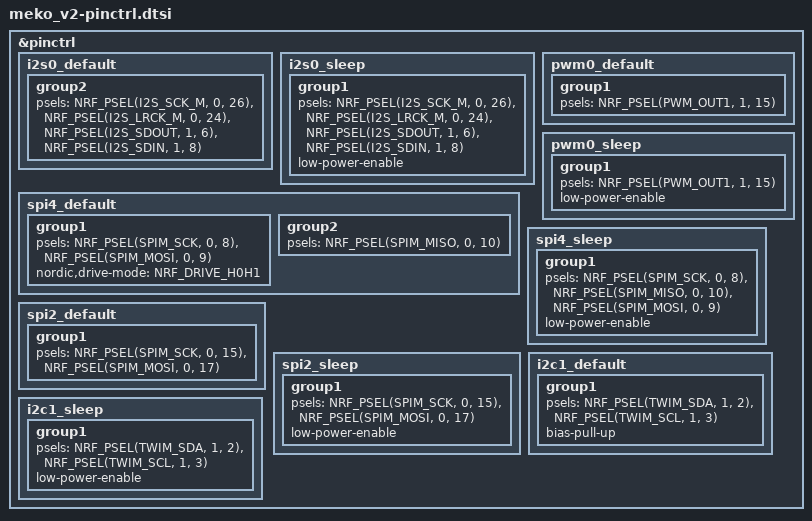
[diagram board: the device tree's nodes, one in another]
&pinctrl {
    i2s0_default: i2s0_default {
        group2 {
            psels = <NRF_PSEL(I2S_SCK_M, 0, 26)>,
                    <NRF_PSEL(I2S_LRCK_M, 0, 24)>,
                    <NRF_PSEL(I2S_SDOUT, 1, 6)>,
                    <NRF_PSEL(I2S_SDIN, 1, 8)>;
        };
    };

    i2s0_sleep: i2s0_sleep {
        group1 {
            psels = <NRF_PSEL(I2S_SCK_M, 0, 26)>,
                    <NRF_PSEL(I2S_LRCK_M, 0, 24)>,
                    <NRF_PSEL(I2S_SDOUT, 1, 6)>,
                    <NRF_PSEL(I2S_SDIN, 1, 8)>;
            low-power-enable;
        };
    };

    pwm0_default: pwm0_default {
        group1 {
            psels = <NRF_PSEL(PWM_OUT1, 1, 15)>;
        };
    };

    pwm0_sleep: pwm0_sleep {
        group1 {
            psels = <NRF_PSEL(PWM_OUT1, 1, 15)>;
            low-power-enable;
        };
    };

    spi4_default: spi4_default {
        group1 {
            psels = <NRF_PSEL(SPIM_SCK, 0, 8)>,
                    <NRF_PSEL(SPIM_MOSI, 0, 9)>;
            /* Workaround for issue with PCA10121 v0.7.0
             * related to SD-card
             */
            nordic,drive-mode = <NRF_DRIVE_H0H1>;
        };

        group2 {
            psels = <NRF_PSEL(SPIM_MISO, 0, 10)>;
        };
    };

    spi4_sleep: spi4_sleep {
        group1 {
            psels = <NRF_PSEL(SPIM_SCK, 0, 8)>,
                    <NRF_PSEL(SPIM_MISO, 0, 10)>,
                    <NRF_PSEL(SPIM_MOSI, 0, 9)>;
            low-power-enable;
        };
    };

    spi2_default: spi2_default {
        group1 {
            psels = <NRF_PSEL(SPIM_SCK, 0, 15)>,
                    <NRF_PSEL(SPIM_MOSI, 0, 17)>; /* DIN */
                };
    };

    spi2_sleep: spi2_sleep {
        group1 {
            psels = <NRF_PSEL(SPIM_SCK, 0, 15)>,
                    <NRF_PSEL(SPIM_MOSI, 0, 17)>;
            low-power-enable;
        };
    };

    i2c1_default: i2c1_default {
        group1 {
            psels = <NRF_PSEL(TWIM_SDA, 1, 2)>,
                    <NRF_PSEL(TWIM_SCL, 1, 3)>;
            bias-pull-up;

        };
    };

    i2c1_sleep: i2c1_sleep {
        group1 {
            psels = <NRF_PSEL(TWIM_SDA, 1, 2)>,
                    <NRF_PSEL(TWIM_SCL, 1, 3)>;
            low-power-enable;
        };
    };
};
